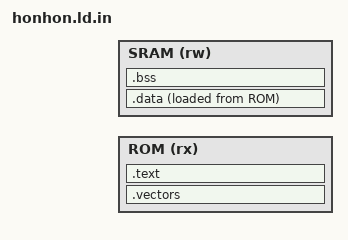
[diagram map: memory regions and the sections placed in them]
OUTPUT_ARCH(riscv)
ENTRY(_start)

MEMORY
{
  ROM (rx) : ORIGIN = @HONHON_ROM_BASE@, LENGTH = @HONHON_ROM_SIZE@
  SRAM (rw) : ORIGIN = @HONHON_SRAM_BASE@, LENGTH = @HONHON_SRAM_SIZE@
}

SECTIONS
{
  .vectors ORIGIN(ROM) : {
    KEEP(*(.vectors))
  } > ROM

  /* Ibex begins execution at boot_addr_i + 0x80. */
  .text ORIGIN(ROM) + 0x80 : {
    KEEP(*(.text.startup))
    *(.text .text.*)
    *(.rodata .rodata.* .srodata .srodata.*)
  } > ROM

  .data : ALIGN(4) {
    __data_start = .;
    PROVIDE(__global_pointer$ = . + 0x800);
    *(.data .data.* .sdata .sdata.*)
    . = ALIGN(4);
    __data_end = .;
  } > SRAM AT> ROM
  __data_load = LOADADDR(.data);

  .bss (NOLOAD) : ALIGN(4) {
    __bss_start = .;
    *(.bss .bss.* .sbss .sbss.* COMMON)
    . = ALIGN(4);
    __bss_end = .;
  } > SRAM

  __stack_top = ORIGIN(SRAM) + LENGTH(SRAM);
  ASSERT(__stack_top - __bss_end >= 1024, "Insufficient SRAM for stack")
}
